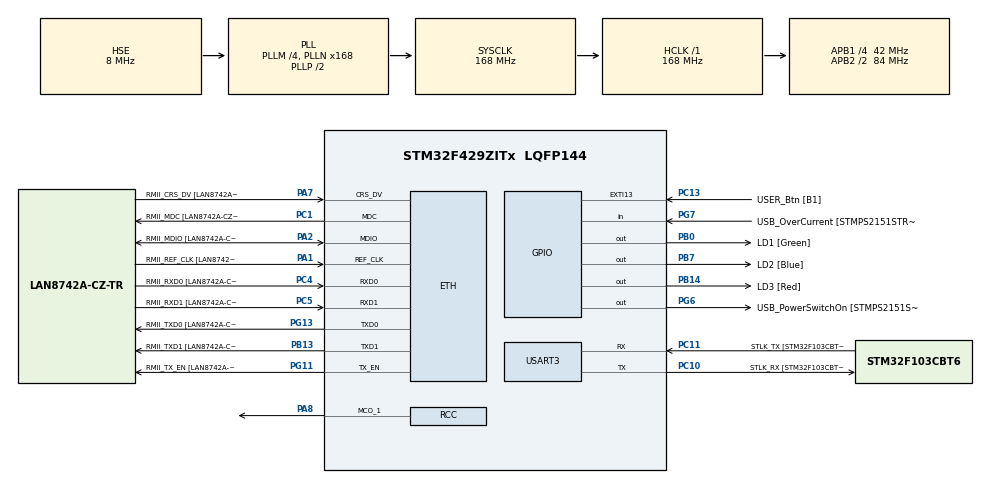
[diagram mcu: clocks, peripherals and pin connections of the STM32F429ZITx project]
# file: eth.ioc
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ETH.MediaInterface=ETH_MEDIA_INTERFACE_RMII
ETH.PHY_Name=LAN8742A_PHY_ADDRESS
ETH.PHY_Value=0
ETH.PhyAddress=0
LWIP.GATEWAY_ADDRESS=192.168.031.001
LWIP.IP_ADDRESS=192.168.031.233
LWIP.LWIP_DBG_MIN_LEVEL=LWIP_DBG_LEVEL_ALL
LWIP.LWIP_DHCP=0
LWIP.NETMASK_ADDRESS=255.255.255.000
LWIP.Version=v2.1.2_Cube
Mcu.Family=STM32F4
Mcu.Name=STM32F429ZITx
Mcu.Package=LQFP144
NVIC.ETH_IRQn=true\:0\:0\:false\:false\:true\:true\:true
NVIC.PriorityGroup=NVIC_PRIORITYGROUP_4
PA1.GPIO_Label=RMII_REF_CLK [LAN8742A-CZ-TR_REFCLK0]
PA1.Mode=RMII
PA1.Signal=ETH_REF_CLK
PA13.GPIO_Label=TMS
PA13.Mode=Serial_Wire
PA13.Signal=SYS_JTMS-SWDIO
PA14.GPIO_Label=TCK
PA14.Mode=Serial_Wire
PA14.Signal=SYS_JTCK-SWCLK
PA2.GPIO_Label=RMII_MDIO [LAN8742A-CZ-TR_MDIO]
PA2.Mode=RMII
PA2.Signal=ETH_MDIO
PA7.GPIO_Label=RMII_CRS_DV [LAN8742A-CZ-TR_CRS_DV]
PA7.Mode=RMII
PA7.Signal=ETH_CRS_DV
PA8.Mode=Clock-out-1
PA8.Signal=RCC_MCO_1
PB0.GPIO_Label=LD1 [Green]
PB0.Signal=GPIO_Output
PB13.GPIO_Label=RMII_TXD1 [LAN8742A-CZ-TR_TXD1]
PB13.Mode=RMII
PB13.Signal=ETH_TXD1
PB14.GPIO_Label=LD3 [Red]
PB14.Signal=GPIO_Output
PB7.GPIO_Label=LD2 [Blue]
PB7.Signal=GPIO_Output
PC1.GPIO_Label=RMII_MDC [LAN8742A-CZ-TR_MDC]
PC1.Mode=RMII
PC1.Signal=ETH_MDC
PC10.GPIO_Label=STLK_RX [STM32F103CBT6_PA3]
PC10.Mode=Asynchronous
PC10.Signal=USART3_TX
PC11.GPIO_Label=STLK_TX [STM32F103CBT6_PA2]
PC11.Mode=Asynchronous
PC11.Signal=USART3_RX
PC13.GPIO_Label=USER_Btn [B1]
PC13.Signal=GPXTI13
PC4.GPIO_Label=RMII_RXD0 [LAN8742A-CZ-TR_RXD0]
PC4.Mode=RMII
PC4.Signal=ETH_RXD0
PC5.GPIO_Label=RMII_RXD1 [LAN8742A-CZ-TR_RXD1]
PC5.Mode=RMII
PC5.Signal=ETH_RXD1
PG11.GPIO_Label=RMII_TX_EN [LAN8742A-CZ-TR_TXEN]
PG11.Mode=RMII
PG11.Signal=ETH_TX_EN
PG13.GPIO_Label=RMII_TXD0 [LAN8742A-CZ-TR_TXD0]
PG13.Mode=RMII
PG13.Signal=ETH_TXD0
PG6.GPIO_Label=USB_PowerSwitchOn [STMPS2151STR_EN]
PG6.Signal=GPIO_Output
PG7.GPIO_Label=USB_OverCurrent [STMPS2151STR_FAULT]
PG7.Signal=GPIO_Input
PH0/OSC_IN.GPIO_Label=MCO [STM32F103CBT6_PA8]
PH0/OSC_IN.Mode=HSE-External-Oscillator
PH0/OSC_IN.Signal=RCC_OSC_IN
PH1/OSC_OUT.Mode=HSE-External-Oscillator
PH1/OSC_OUT.Signal=RCC_OSC_OUT
ProjectManager.HeapSize=0x2000
ProjectManager.StackSize=0x4000
ProjectManager.TargetToolchain=Makefile
RCC.48MHZClocksFreq_Value=48000000
RCC.AHBFreq_Value=168000000
RCC.APB1CLKDivider=RCC_HCLK_DIV4
RCC.APB1Freq_Value=42000000
RCC.APB1TimFreq_Value=84000000
RCC.APB2CLKDivider=RCC_HCLK_DIV2
RCC.APB2Freq_Value=84000000
RCC.APB2TimCLKDivider=2
RCC.APB2TimFreq_Value=168000000
RCC.CortexFreq_Value=168000000
RCC.HCLKFreq_Value=168000000
RCC.HSE_VALUE=8000000
RCC.HSI_VALUE=16000000
RCC.PLLM=4
RCC.PLLMUL=RCC_PLL_MUL9
RCC.PLLN=168
RCC.PLLQ=7
RCC.PLLSourceVirtual=RCC_PLLSOURCE_HSE
RCC.PRESCALERUSB=RCC_USBCLKSOURCE_PLL_DIV1_5
RCC.RCC_MCODiv1=RCC_MCODIV_2
RCC.SYSCLKFreq_VALUE=168000000
RCC.SYSCLKSource=RCC_SYSCLKSOURCE_PLLCLK
RCC.SYSCLKSourceVirtual=RCC_SYSCLKSOURCE_PLLCLK
RCC.USBFreq_Value=48000000
RCC.VCOOutputFreq_Value=336000000
USART3.VirtualMode=VM_ASYNC
VP_LWIP_VS_Enabled.Mode=Enabled
board=NUCLEO-F429ZI

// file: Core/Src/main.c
/* USER CODE BEGIN Header */
/**
  ******************************************************************************
  * @file           : main.c
  * @brief          : Main program body
  ******************************************************************************
  * @attention
  *
  * <h2><center>&copy; Copyright (c) 2022 STMicroelectronics.
  * All rights reserved.</center></h2>
  *
  * This software component is licensed by ST under Ultimate Liberty license
  * SLA0044, the "License"; You may not use this file except in compliance with
  * the License. You may obtain a copy of the License at:
  *                             www.st.com/SLA0044
  *
  ******************************************************************************
  */
/* USER CODE END Header */
#include "main.h"
#include "lwip.h"
#include "usart.h"
#include "gpio.h"

/* USER CODE BEGIN Includes */
#include "retarget.h"
#include <stdio.h>
/* USER CODE END Includes */

void SystemClock_Config(void);

int main(void)
{

  /* MCU Configuration--------------------------------------------------------*/

  /* Reset of all peripherals, Initializes the Flash interface and the Systick. */
  HAL_Init();

  /* Configure the system clock */
  SystemClock_Config();

  /* Initialize all configured peripherals */
  MX_GPIO_Init();
  MX_USART3_UART_Init();
  MX_LWIP_Init();
  /* USER CODE BEGIN 2 */
  RetargetInit(&huart3);
  printf("ETH Initialization Success\n");

  /* USER CODE END 2 */

  /* Infinite loop */
  /* USER CODE BEGIN WHILE */

  while (1)
  {
    MX_LWIP_Process();
    /* USER CODE END WHILE */

  }
}

void SystemClock_Config(void)
{
  RCC_OscInitTypeDef RCC_OscInitStruct = {0};
  RCC_ClkInitTypeDef RCC_ClkInitStruct = {0};

  /** Configure the main internal regulator output voltage
  */
  __HAL_RCC_PWR_CLK_ENABLE();
  __HAL_PWR_VOLTAGESCALING_CONFIG(PWR_REGULATOR_VOLTAGE_SCALE1);
  /** Initializes the RCC Oscillators according to the specified parameters
  * in the RCC_OscInitTypeDef structure.
  */
  RCC_OscInitStruct.OscillatorType = RCC_OSCILLATORTYPE_HSI|RCC_OSCILLATORTYPE_HSE;
  RCC_OscInitStruct.HSEState = RCC_HSE_ON;
  RCC_OscInitStruct.HSIState = RCC_HSI_ON;
  RCC_OscInitStruct.HSICalibrationValue = RCC_HSICALIBRATION_DEFAULT;
  RCC_OscInitStruct.PLL.PLLState = RCC_PLL_ON;
  RCC_OscInitStruct.PLL.PLLSource = RCC_PLLSOURCE_HSE;
  RCC_OscInitStruct.PLL.PLLM = 4;
  RCC_OscInitStruct.PLL.PLLN = 168;
  RCC_OscInitStruct.PLL.PLLP = RCC_PLLP_DIV2;
  RCC_OscInitStruct.PLL.PLLQ = 7;
  if (HAL_RCC_OscConfig(&RCC_OscInitStruct) != HAL_OK)
  {
    Error_Handler();
  }
  /** Initializes the CPU, AHB and APB buses clocks
  */
  RCC_ClkInitStruct.ClockType = RCC_CLOCKTYPE_HCLK|RCC_CLOCKTYPE_SYSCLK
                              |RCC_CLOCKTYPE_PCLK1|RCC_CLOCKTYPE_PCLK2;
  RCC_ClkInitStruct.SYSCLKSource = RCC_SYSCLKSOURCE_PLLCLK;
  RCC_ClkInitStruct.AHBCLKDivider = RCC_SYSCLK_DIV1;
  RCC_ClkInitStruct.APB1CLKDivider = RCC_HCLK_DIV4;
  RCC_ClkInitStruct.APB2CLKDivider = RCC_HCLK_DIV2;

  if (HAL_RCC_ClockConfig(&RCC_ClkInitStruct, FLASH_LATENCY_5) != HAL_OK)
  {
    Error_Handler();
  }
  HAL_RCC_MCOConfig(RCC_MCO1, RCC_MCO1SOURCE_HSI, RCC_MCODIV_2);
}

void Error_Handler(void)
{
  __disable_irq();
  while (1)
  {
  }
}

/************************ (C) COPYRIGHT STMicroelectronics *****END OF FILE****/
